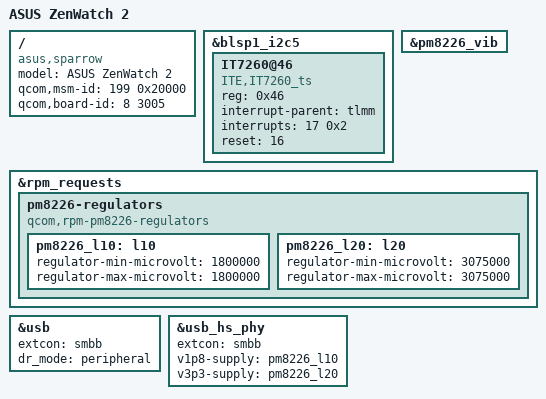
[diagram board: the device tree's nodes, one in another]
// SPDX-License-Identifier: BSD-3-Clause
/*
 * Copyright (c) 2021, Luca Weiss <luca@z3ntu.xyz>
 */

/dts-v1/;

#include "qcom-msm8226.dtsi"
#include "qcom-pm8226.dtsi"

/ {
	model = "ASUS ZenWatch 2";
	compatible = "asus,sparrow", "qcom,apq8026";
	qcom,msm-id = <199 0x20000>;
	qcom,board-id = <8 3005>;
};

&blsp1_i2c5 {
	status = "okay";

	IT7260@46 {
		compatible = "ITE,IT7260_ts";
		reg = <0x46>;
		interrupt-parent = <&tlmm>;
		interrupts = <17 0x2>;
		reset = <16>;
	};
};

&pm8226_vib {
	status = "okay";
};

&rpm_requests {
	pm8226-regulators {
		compatible = "qcom,rpm-pm8226-regulators";

		pm8226_l10: l10 {
			regulator-min-microvolt = <1800000>;
			regulator-max-microvolt = <1800000>;
		};
		pm8226_l20: l20 {
			regulator-min-microvolt = <3075000>;
			regulator-max-microvolt = <3075000>;
		};
	};
};

&usb {
	status = "okay";
	extcon = <&smbb>;
	dr_mode = "peripheral";
};

&usb_hs_phy {
	extcon = <&smbb>;
	v1p8-supply = <&pm8226_l10>;
	v3p3-supply = <&pm8226_l20>;
};
